AUTOSAR XML (schema 00050)
package /SwComponentDesign
  port interface PlatformHealthManagementInterface
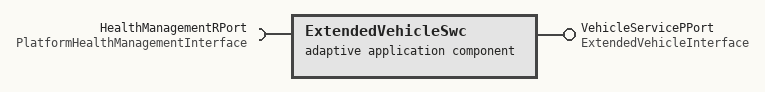
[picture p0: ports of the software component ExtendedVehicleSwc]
  adaptive application sw component type ExtendedVehicleSwc
    provide port VehicleServicePPort: provided-interface=ExtendedVehicleInterface
    require port HealthManagementRPort: required-interface=PlatformHealthManagementInterface
  adaptive application sw component type WatchdogSwc
    require port VehicleServiceRPort: required-interface=ExtendedVehicleInterface
